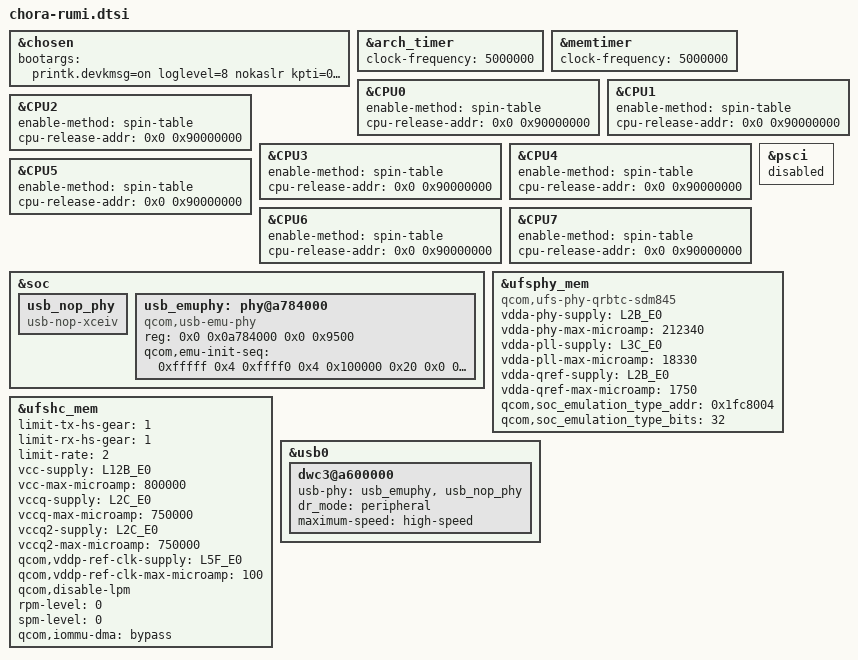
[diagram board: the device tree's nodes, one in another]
// SPDX-License-Identifier: BSD-3-Clause
/*
 * Copyright (c) Qualcomm Technologies, Inc. and/or its subsidiaries.
 */

&chosen {
	bootargs = "printk.devkmsg=on loglevel=8 nokaslr kpti=0 log_buf_len=256K swiotlb=0 slub_debug=- cpufreq.default_governor=performance";
};

&arch_timer {
	clock-frequency = <5000000>;
};

&memtimer {
	clock-frequency = <5000000>;
};

&CPU0 {
	enable-method = "spin-table"; /* TODO: Update to psci */
	cpu-release-addr = <0x0 0x90000000>;
};

&CPU1 {
	enable-method = "spin-table"; /* TODO: Update to psci */
	cpu-release-addr = <0x0 0x90000000>;
};

&CPU2 {
	enable-method = "spin-table"; /* TODO: Update to psci */
	cpu-release-addr = <0x0 0x90000000>;
};

&CPU3 {
	enable-method = "spin-table"; /* TODO: Update to psci */
	cpu-release-addr = <0x0 0x90000000>;
};

&CPU4 {
	enable-method = "spin-table"; /* TODO: Update to psci */
	cpu-release-addr = <0x0 0x90000000>;
};

&CPU5 {
	enable-method = "spin-table"; /* TODO: Update to psci */
	cpu-release-addr = <0x0 0x90000000>;
};

&CPU6 {
	enable-method = "spin-table"; /* TODO: Update to psci */
	cpu-release-addr = <0x0 0x90000000>;
};

&CPU7 {
	enable-method = "spin-table"; /* TODO: Update to psci */
	cpu-release-addr = <0x0 0x90000000>;
};

&psci {
	status = "disabled";
};

&soc {
	usb_nop_phy: usb_nop_phy {
		compatible = "usb-nop-xceiv";
	};

	usb_emuphy: phy@a784000 {
		compatible = "qcom,usb-emu-phy";
		reg = <0x0 0x0a784000 0x0 0x9500>;

		qcom,emu-init-seq = <0xfffff 0x4
			0xffff0 0x4
			0x100000 0x20
			0x0 0x20
			0x000101F0 0x20
			0x00100000 0x3c
			0x0 0x3c
			0x0 0x4
			0x9 0x14>;
	};
};

&ufsphy_mem {
	compatible = "qcom,ufs-phy-qrbtc-sdm845";

	/* VDDA_UFS_CORE */
	vdda-phy-supply = <&L2B_E0>;
	vdda-phy-max-microamp = <212340>;

	/* VDDA_UFS_0_1P2 */
	vdda-pll-supply = <&L3C_E0>;
	vdda-pll-max-microamp = <18330>;

	/* Qref power supply, Refer Qref diagram */
	vdda-qref-supply = <&L2B_E0>;
	vdda-qref-max-microamp = <1750>;

	/* Detect whether RH132 card based sequences to be used */
	qcom,soc_emulation_type_addr = <0x1fc8004>;
	qcom,soc_emulation_type_bits = <32>;

	status = "ok";
};

&ufshc_mem {
	limit-tx-hs-gear = <1>;
	limit-rx-hs-gear = <1>;
	limit-rate = <2>; /* HS Rate-B */

	vcc-supply = <&L12B_E0>;
	vcc-max-microamp = <800000>;

	vccq-supply = <&L2C_E0>;
	vccq-max-microamp = <750000>;

	vccq2-supply = <&L2C_E0>;
	vccq2-max-microamp = <750000>;

	/* VDD_PX10 is voted for the ufs_reset_n */
	qcom,vddp-ref-clk-supply = <&L5F_E0>;
	qcom,vddp-ref-clk-max-microamp = <100>;

	qcom,disable-lpm;
	rpm-level = <0>;
	spm-level = <0>;

	qcom,iommu-dma = "bypass";
	status = "ok";
};

&usb0 {
	dwc3@a600000 {
		usb-phy = <&usb_emuphy>, <&usb_nop_phy>;
		dr_mode = "peripheral";
		maximum-speed = "high-speed";
	};
};
